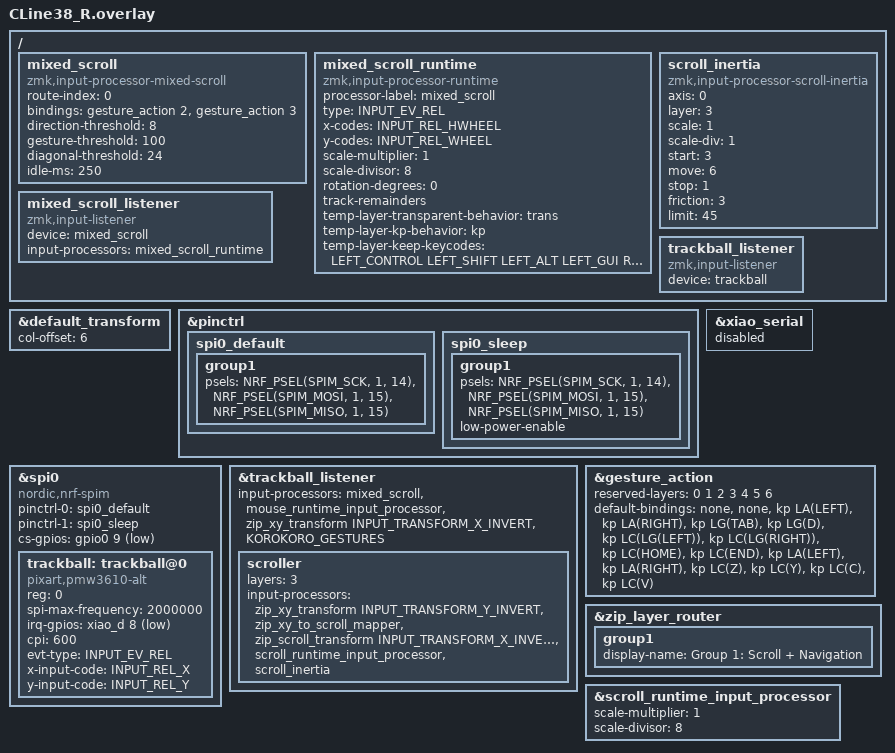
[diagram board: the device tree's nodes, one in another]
#include "CLine38.dtsi"
#include <zephyr/dt-bindings/input/input-event-codes.h>
#include <input/processors.dtsi>
#include <input/processors/runtime-input-processor.dtsi>
#include <behaviors/battery_history_request.dtsi>
#include <presets/gesture_six_groups.dtsi>

&default_transform {
    col-offset = <6>;
};


/ {
    mixed_scroll: mixed_scroll {
        compatible = "zmk,input-processor-mixed-scroll";
        #input-processor-cells = <0>;
        route-index = <0>; // ころころKitのGroup 1。保存済みの対象レイヤーにも追従する。
        bindings = <&gesture_action 2>, <&gesture_action 3>;
        direction-threshold = <8>;
        gesture-threshold = <100>;
        diagonal-threshold = <24>;
        idle-ms = <250>;
    };

    // このモードは通常マウスの倍率を通さず、専用の倍率を一度だけ適用する。
    // レイヤー3のscroll設定と分離し、慣性プロセッサも接続しない。
    mixed_scroll_runtime: mixed_scroll_runtime {
        compatible = "zmk,input-processor-runtime";
        #input-processor-cells = <0>;
        processor-label = "mixed_scroll";
        type = <INPUT_EV_REL>;
        x-codes = <INPUT_REL_HWHEEL>;
        y-codes = <INPUT_REL_WHEEL>;
        scale-multiplier = <1>;
        scale-divisor = <8>;
        rotation-degrees = <0>;
        track-remainders;
        temp-layer-transparent-behavior = <&trans>;
        temp-layer-kp-behavior = <&kp>;
        temp-layer-keep-keycodes = <LEFT_CONTROL LEFT_SHIFT LEFT_ALT LEFT_GUI RIGHT_CONTROL RIGHT_SHIFT RIGHT_ALT RIGHT_GUI>;
    };

    mixed_scroll_listener {
        compatible = "zmk,input-listener";
        device = <&mixed_scroll>;
        input-processors = <&mixed_scroll_runtime>;
    };

    // DYA Studioによる倍率・軸変換後の値を追跡するため、慣性出力は1:1。
    // 初期600 CPI / 1:8に合わせた開始値。実機で必要に応じて調整する。
    scroll_inertia: scroll_inertia {
        compatible = "zmk,input-processor-scroll-inertia";
        #input-processor-cells = <0>;
        axis = <0>;
        layer = <3>;
        scale = <1>;
        scale-div = <1>;
        start = <3>;
        move = <6>;
        stop = <1>;
        friction = <3>;
        limit = <45>;
    };

    trackball_listener {
        status = "okay";
        compatible = "zmk,input-listener";
        device = <&trackball>;
    };
};

&pinctrl {
    spi0_default: spi0_default {
        group1 {
            psels = <NRF_PSEL(SPIM_SCK, 1, 14)>,
                <NRF_PSEL(SPIM_MOSI, 1, 15)>,
                <NRF_PSEL(SPIM_MISO, 1, 15)>;
        };
    };

    spi0_sleep: spi0_sleep {
        group1 {
            psels = <NRF_PSEL(SPIM_SCK, 1, 14)>,
                <NRF_PSEL(SPIM_MOSI, 1, 15)>,
                <NRF_PSEL(SPIM_MISO, 1, 15)>;
            low-power-enable;
        };
    };
};


&xiao_serial { status = "disabled"; };

&spi0 {
    status = "okay";
    compatible = "nordic,nrf-spim";
    pinctrl-0 = <&spi0_default>;
    pinctrl-1 = <&spi0_sleep>;
    pinctrl-names = "default", "sleep";
    cs-gpios = <&gpio0 9 GPIO_ACTIVE_LOW>;  //P0.09を指定(CS)

    trackball: trackball@0 {
        status = "okay";
        compatible = "pixart,pmw3610-alt";
        reg = <0>;
        spi-max-frequency = <2000000>;
        irq-gpios = <&xiao_d 8 (GPIO_ACTIVE_LOW | GPIO_PULL_UP)>;
        cpi = <600>;
        //swap-xy;
        evt-type = <INPUT_EV_REL>;
        x-input-code = <INPUT_REL_X>;
        y-input-code = <INPUT_REL_Y>;
    };
};

// Overrides for the input listener node
&trackball_listener {
    status = "okay";
    input-processors = <&mixed_scroll>,                       //Group 1を生のXYから先に分岐
        <&mouse_runtime_input_processor>,
        //<&zip_xy_transform INPUT_TRANSFORM_Y_INVERT>;         //Y軸反転
        //<&zip_xy_transform INPUT_TRANSFORM_XY_SWAP>,        //X軸とY軸の入れ替え
        <&zip_xy_transform INPUT_TRANSFORM_X_INVERT>,       //X軸反転
        <KOROKORO_GESTURES>;                               //ころころKit: レイヤー7〜10
        //<&zip_temp_layer 2 1000>;                            //オートマウスレイヤーの選択;


    scroller {
        layers = <3>;
        input-processors = 
            // <&zip_xy_transform INPUT_TRANSFORM_XY_SWAP>,        //X軸とY軸の入れ替え
            // <&zip_xy_transform INPUT_TRANSFORM_X_INVERT>,       //X軸反転
            <&zip_xy_transform INPUT_TRANSFORM_Y_INVERT>,       //Y軸反転
            <&zip_xy_to_scroll_mapper>,                         //スクロールモードに変更
            <&zip_scroll_transform INPUT_TRANSFORM_X_INVERT>,   //スクロールのX軸反転
            //<&zip_scroll_transform INPUT_TRANSFORM_Y_INVERT>,   //スクロールのY軸反転
            <&scroll_runtime_input_processor>,                  //スクロール量・軸スナップをDYA Studioから調整可能に
            <&scroll_inertia>;                                  //最終スクロール値を追跡し、レイヤー3解除で停止
    };
};

// 標準プリセット: 6グループ / 24スロット。初期状態ではグループ1〜4が
// レイヤー7〜10で有効、グループ5〜6は未割り当て。
// ベースチェーンに置くことで、ころころKitから対象レイヤーを変更できる。
// 0〜6は既存用途として予約する。レイヤー3のスクロール上書きも維持する。
&gesture_action {
    reserved-layers = <0 1 2 3 4 5 6>;
    // Group 1の上下スロットは使用しない。左右のみころころKitで変更可能。
    // Group 2〜4の初期値は標準プリセットと同一。
    default-bindings =
        <&none>, <&none>, <&kp LA(LEFT)>, <&kp LA(RIGHT)>,
        <&kp LG(TAB)>, <&kp LG(D)>, <&kp LC(LG(LEFT))>, <&kp LC(LG(RIGHT))>,
        <&kp LC(HOME)>, <&kp LC(END)>, <&kp LA(LEFT)>, <&kp LA(RIGHT)>,
        <&kp LC(Z)>, <&kp LC(Y)>, <&kp LC(C)>, <&kp LC(V)>;
};

&zip_layer_router {
    group1 {
        display-name = "Group 1: Scroll + Navigation";
    };
};

// スクロール用のランタイム入力プロセッサ。
//
// 従来の <&zip_scroll_scaler 1 8> を置き換えたもの。scaler は再ビルドしないと
// 変更できなかったが、これに替えるとスクロール量を DYA Studio の
// 「トラックボール設定」から調整できるようになる。あわせて軸スナップ
// (移動を縦横どちらかに固定する機能。表計算ソフトなどで有用) も利用できる。
//
// 注意: このノードは runtime-input-processor.dtsi 内で /omit-if-no-ref/ 指定
// されているため、ここで参照して初めて firmware に組み込まれる。参照が無いと
// DYA Studio のプロセッサ一覧にも現れない。
//
// 下の初期値は従来の <&zip_scroll_scaler 1 8> と同じ 1/8 倍。
// 一度 DYA Studio で変更すると、そちらが保存されて以後優先される。
&scroll_runtime_input_processor {
    scale-multiplier = <1>;
    scale-divisor = <8>;
};
